# N32A052 register map
Vendor: Nationstech Ltd.; File version: 1.0
Registers are 32-bit, read-write, reset 0x0 unless marked. A register's access mark holds for its fields unless they carry their own. Offsets are from the block's base; lines under a group give offsets from that group; [hi:lo] are bit positions; {n}, {i} and the like mark numbered series; 'fields as' and 'values as' point back to an identical list; <NAME> marks a mode.

## Memory map
0x40000000 BEEPER size 0x400 — Beeper unit
0x40000400 UART3 size 0x400
0x40000800 UART4 size 0x400
0x40000C00 UART5 size 0x400
0x40001000 TIM6 size 0x400 — Basic timer
0x40001C00 CAN size 0x400 — Controller area network
0x40002000 DAC size 0x400 — digital to analog converter
0x40002400 COMP size 0x400 — comparator
0x40002800 RTC size 0x400 — Real time clock
0x40002C00 WWDG size 0x400 — window watchdog
0x40003000 IWDG size 0x400 — Independent watchdog
0x40003C00 LCD size 0x400 — Liquid Crystal Display
0x40005400 I2C1 size 0x400 — Inter integrated circuit
0x40005800 I2C2 size 0x400
0x40007000 PWR size 0x400 — Power control
0x40010000 AFIO size 0x400 — Alternate function I/O
0x40010400 EXTI size 0x400 — external interrupt/event controller
0x40010800 GPIOA size 0x400 — General purpose I/O
0x40010C00 GPIOB size 0x400
0x40011000 GPIOC size 0x400
0x40011C00 GPIOD size 0x400
0x40012000 SPI1 size 0x400 — Serial peripheral interface
0x40012400 TIM4 size 0x400
0x40012800 TIM5 size 0x400
0x40012C00 TIM1 size 0x400 — Advanced timer
0x40013000 TIM3 size 0x400
0x40013400 TIM2 size 0x400 — General purpose timer
0x40013800 UART1 size 0x400 — Universal asynchronous receiver transmitter
0x40013C00 UART2 size 0x400
0x40014000 SPI3 size 0x400
0x40014400 SPI2 size 0x400
0x40020000 DMA size 0x400 — Direct memory access controller
0x40020800 ADC size 0x400 — analog to digital converter
0x40021000 RCC size 0x400 — Reset and clock control
0x40022000 FLASH size 0x400 — interal FLASH controller
0x40023000 CRC size 0x400 — cyclic redundancy check

## Interrupts
0 WWDG — WWDG interrupt
1 PVD (PWR) — PVD through EXTI line detection interrupt
2 RTC — RTC global interrupt
4 FLASH — FLASH interrupt
5 RCC — RCC interrupt
6 EXTI0_1 (EXTI) — EXTI0/1 interrupt
7 EXTI2_3 (EXTI) — EXTI2/3 interrupt
8 EXTI4_15 (EXTI) — EXTI4/5/6/7/8/9/10/11/12/13/14/15 interrupt
10 DMA_Channel1_2 (DMA) — DMA channel1 channel2 interrupt
11 DMA_Channel3_4_5 (DMA) — DMA channel3 channel4 channel5 interrupt
12 TIM4 — TIM4 global interrupt
13 TIM1_BRK_UP_TRG_COM (TIM1) — TIM1 Break/Update/Trigger/Commutation interrupt
14 TIM1_CC (TIM1) — TIM1 Capture Compare interrupt
15 CAN — CAN interrupts
16 TIM3 — TIM3 global interrupt
17 UART3_4 (UART3) — UART3_4 global interrupt
18 TIM5 — TIM5 global interrupt
19 TIM6 — TIM6 global interrupt
20 TIM2 — TIM2 global interrupt
21 ADC — ADC global interrupt
22 SPI2 — SPI2 global interrupt
23 I2C1 — I2C1 global interrupt
24 I2C2 — I2C2 Global interrupt
25 SPI1 — SPI1 global interrupt
26 UART1 — UART1 global interrupt
27 SPI3 — SPI3 global interrupt
28 UART5 — UART5 global interrupt
29 LCD — LCD global interrupt
30 UART2 — UART2 global interrupt
31 COMP — COMP interrupt

## ADC — analog to digital converter
Base 0x40020800
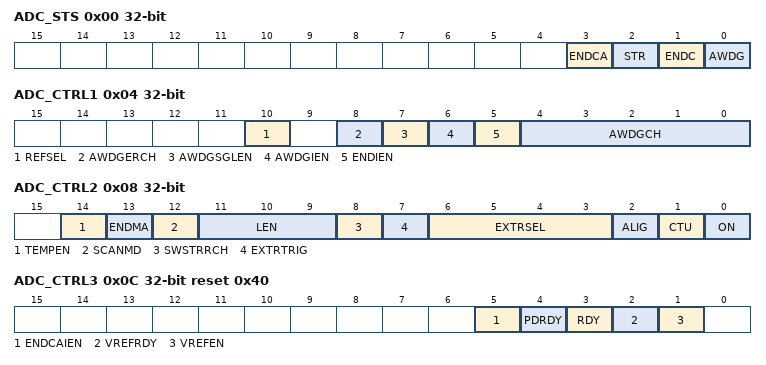
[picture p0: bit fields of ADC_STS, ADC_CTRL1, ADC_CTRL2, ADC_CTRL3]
0x00 ADC_STS
  [3] ENDCA, [2] STR, [1] ENDC, [0] AWDG
0x04 ADC_CTRL1 (reset mask 0x1FF)
  [10] REFSEL, [8] AWDGERCH, [7] AWDGSGLEN, [6] AWDGIEN, [5] ENDIEN, [4:0] AWDGCH
0x08 ADC_CTRL2
  [14] TEMPEN, [13] ENDMA, [12] SCANMD, [11:9] LEN, [8] SWSTRRCH, [7] EXTRTRIG, [6:3] EXTRSEL, [2] ALIG, [1] CTU, [0] ON
0x0C ADC_CTRL3 reset 0x40
  [5] ENDCAIEN, [4] PDRDY, [3] RDY, [2] VREFRDY, [1] VREFEN
0x10 ADC_SAMPT
  [4:0] SAMP
0x14 ADC_WDGHIGH reset 0xFFF
  [11:0] HTH
0x18 ADC_WDGLOW
  [11:0] LTH
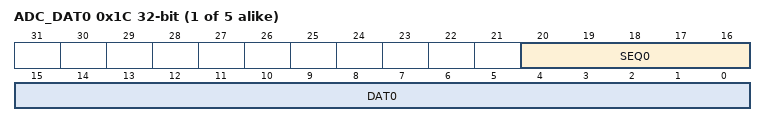
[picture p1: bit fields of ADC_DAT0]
{0x1C+4i} ADC_DAT{i} (i=0..4)
  [20:16] SEQ{i}, [15:0] DAT{i}

## BEEPER — Beeper unit
Base 0x40000000
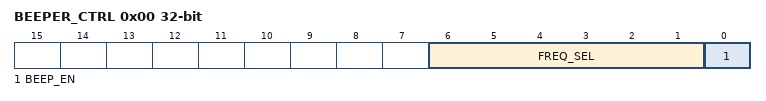
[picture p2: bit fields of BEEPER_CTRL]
0x00 BEEPER_CTRL
  [6:1] FREQ_SEL, [0] BEEP_EN

## CAN — Controller area network
Base 0x40001C00
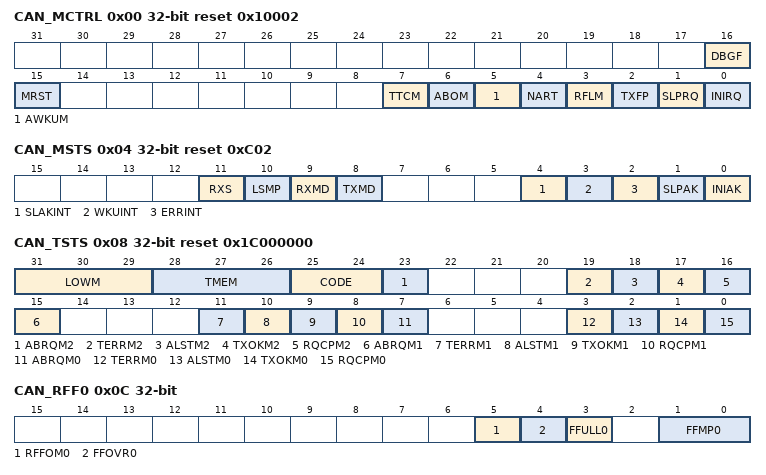
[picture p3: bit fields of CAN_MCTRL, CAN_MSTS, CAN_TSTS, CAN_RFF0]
0x00 CAN_MCTRL reset 0x10002
  [16] DBGF, [15] MRST, [7] TTCM, [6] ABOM, [5] AWKUM, [4] NART, [3] RFLM, [2] TXFP, [1] SLPRQ, [0] INIRQ
0x04 CAN_MSTS reset 0xC02
  [11] RXS, [10] LSMP, [9] RXMD, [8] TXMD, [4] SLAKINT, [3] WKUINT, [2] ERRINT, [1] SLPAK, [0] INIAK
0x08 CAN_TSTS reset 0x1C000000
  [31:29] LOWM, [28:26] TMEM, [25:24] CODE, [23] ABRQM2, [19] TERRM2, [18] ALSTM2, [17] TXOKM2, [16] RQCPM2, [15] ABRQM1, [11] TERRM1, [10] ALSTM1, [9] TXOKM1, [8] RQCPM1, [7] ABRQM0, [3] TERRM0, [2] ALSTM0, [1] TXOKM0, [0] RQCPM0
0x0C CAN_RFF0
  [5] RFFOM0, [4] FFOVR0, [3] FFULL0, [1:0] FFMP0
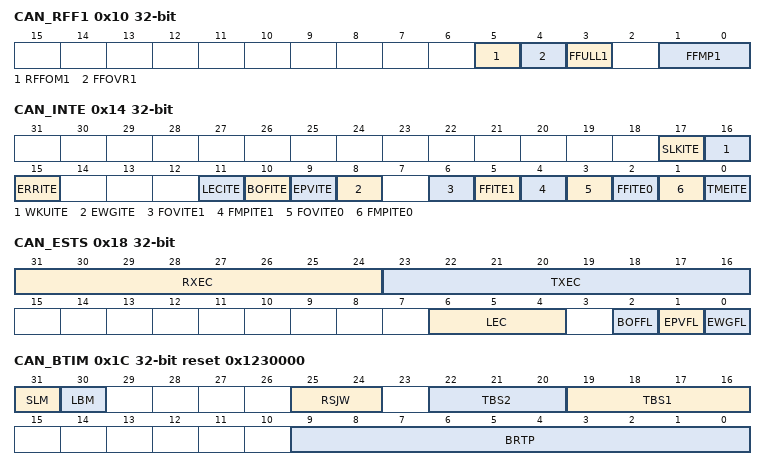
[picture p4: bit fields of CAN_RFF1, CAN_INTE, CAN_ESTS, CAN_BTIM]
0x10 CAN_RFF1
  [5] RFFOM1, [4] FFOVR1, [3] FFULL1, [1:0] FFMP1
0x14 CAN_INTE
  [17] SLKITE, [16] WKUITE, [15] ERRITE, [11] LECITE, [10] BOFITE, [9] EPVITE, [8] EWGITE, [6] FOVITE1, [5] FFITE1, [4] FMPITE1, [3] FOVITE0, [2] FFITE0, [1] FMPITE0, [0] TMEITE
0x18 CAN_ESTS
  [31:24] RXEC, [23:16] TXEC, [6:4] LEC, [2] BOFFL, [1] EPVFL, [0] EWGFL
0x1C CAN_BTIM reset 0x1230000
  [31] SLM, [30] LBM, [25:24] RSJW, [22:20] TBS2, [19:16] TBS1, [9:0] BRTP
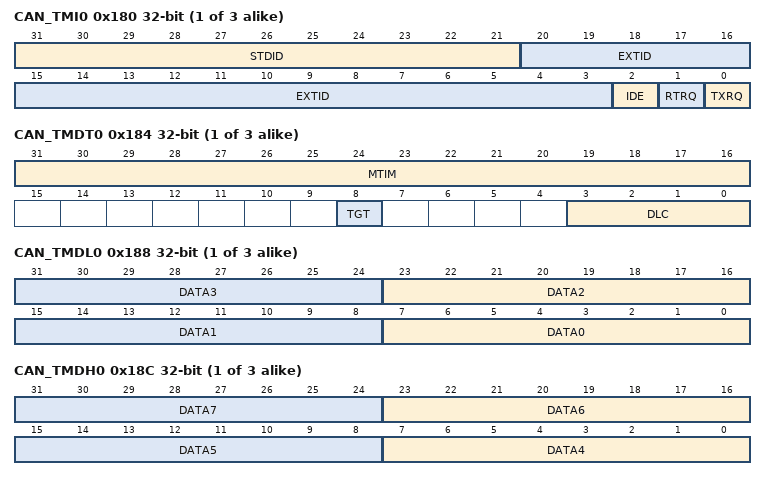
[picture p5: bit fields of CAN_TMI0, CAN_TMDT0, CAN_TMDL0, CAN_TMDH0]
{0x180+0x10*i} CAN_TMI{i} (i=0..2)
  [31:21] STDID, [20:3] EXTID, [2] IDE, [1] RTRQ, [0] TXRQ
{0x184+0x10*i} CAN_TMDT{i} (i=0..2)
  [31:16] MTIM, [8] TGT, [3:0] DLC
{0x188+0x10*i} CAN_TMDL{i} (i=0..2)
  [8n+7:8n] DATA{n} (n=0..3)
{0x18C+0x10*i} CAN_TMDH{i} (i=0..2)
  [8n-25:8n-32] DATA{n} (n=4..7)
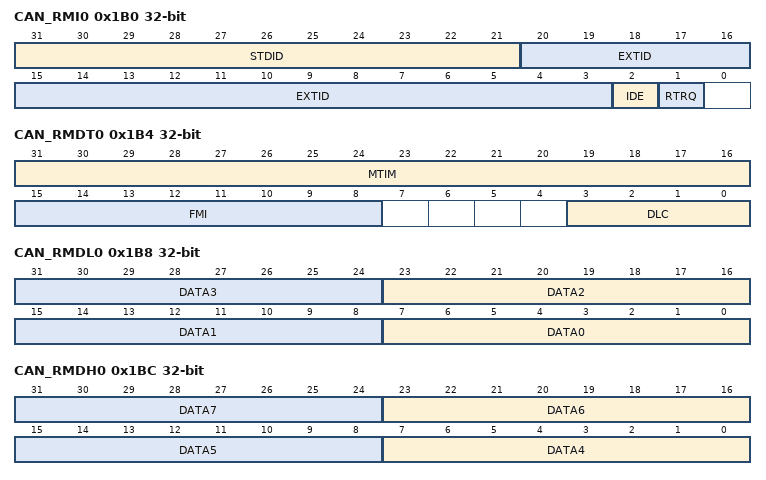
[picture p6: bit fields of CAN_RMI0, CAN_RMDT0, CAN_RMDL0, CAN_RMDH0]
0x1B0 CAN_RMI0
  [31:21] STDID, [20:3] EXTID, [2] IDE, [1] RTRQ
0x1B4 CAN_RMDT0
  [31:16] MTIM, [15:8] FMI, [3:0] DLC
0x1B8 CAN_RMDL0
  [8n+7:8n] DATA{n} (n=0..3)
0x1BC CAN_RMDH0
  [8n-25:8n-32] DATA{n} (n=4..7)
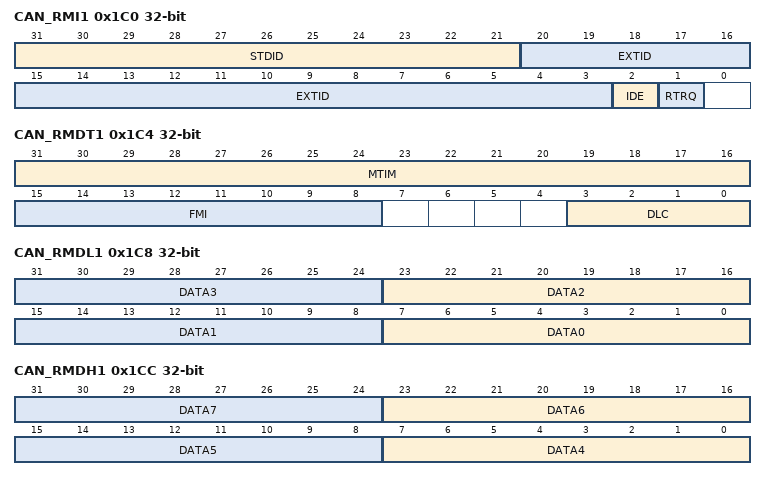
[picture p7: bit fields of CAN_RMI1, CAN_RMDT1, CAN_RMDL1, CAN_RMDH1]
0x1C0 CAN_RMI1
  [31:21] STDID, [20:3] EXTID, [2] IDE, [1] RTRQ
0x1C4 CAN_RMDT1
  [31:16] MTIM, [15:8] FMI, [3:0] DLC
0x1C8 CAN_RMDL1
  [8n+7:8n] DATA{n} (n=0..3)
0x1CC CAN_RMDH1
  [8n-25:8n-32] DATA{n} (n=4..7)
0x200 CAN_FMC reset 0x1
  [0] FINITM
0x204 CAN_FM1
  [13:0] FB
0x20C CAN_FS1
  [13:0] FSC
0x214 CAN_FFA1
  [13:0] FAF
0x21C CAN_FA1
  [13:0] FAC
{0x240+8i} CAN_F{i}B1 (i=0..13)
  [31:0] FBC
{0x244+8i} CAN_F{i}B2 (i=0..13)
  [31:0] FBC
